AUTOSAR XML (schema 00050)
package /Pkg_DegManager_A/ComponentTypes
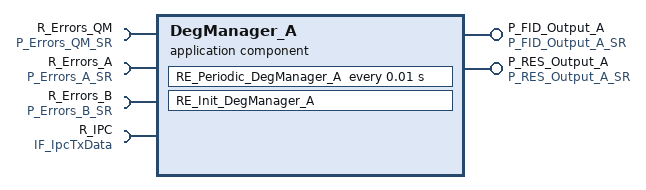
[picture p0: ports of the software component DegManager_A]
  application sw component type DegManager_A
    provide port P_FID_Output_A: nonqueued-sender-com-spec{data-element=FID_A, init-value=constant-reference=init_FID_A}, provided-interface=P_FID_Output_A_SR
    require port R_Errors_QM: nonqueued-receiver-com-spec{data-element=Errors_QM, init-value=constant-reference=init_Errors_QM}, required-interface=P_Errors_QM_SR
    require port R_Errors_A: nonqueued-receiver-com-spec{data-element=Errors_A, init-value=constant-reference=init_Errors_A}, required-interface=P_Errors_A_SR
    require port R_Errors_B: nonqueued-receiver-com-spec{data-element=Errors_B, init-value=constant-reference=init_Errors_B}, required-interface=P_Errors_B_SR
    provide port P_RES_Output_A: nonqueued-sender-com-spec{data-element=RES_A, init-value=constant-reference=init_RES_A}, provided-interface=P_RES_Output_A_SR
    require port R_IPC: client-com-spec=IPC_Write_v, required-interface=IF_IpcTxData
    behavior DegManager_A_InternalBehavior: handle-termination-and-restart=NO-SUPPORT
      timing event TMT_RE_Periodic_DegManager_A: start-on-event=RE_Periodic_DegManager_A, period=0.01
      init event InitEvent: start-on-event=RE_Init_DegManager_A
      port-api-options:
        enable-take-address=false, error-handling=NO-TRANSFORMER-ERROR-HANDLING, indirect-api=false, port=P_FID_Output_A
        enable-take-address=false, error-handling=NO-TRANSFORMER-ERROR-HANDLING, indirect-api=false, port=R_Errors_A
        enable-take-address=false, error-handling=NO-TRANSFORMER-ERROR-HANDLING, indirect-api=false, port=R_Errors_B
        enable-take-address=false, error-handling=NO-TRANSFORMER-ERROR-HANDLING, indirect-api=false, port=R_Errors_QM
        enable-take-address=false, error-handling=NO-TRANSFORMER-ERROR-HANDLING, indirect-api=false, port=P_RES_Output_A
        enable-take-address=false, error-handling=NO-TRANSFORMER-ERROR-HANDLING, indirect-api=false, port=R_IPC
      runnable RE_Periodic_DegManager_A  # Periodic Runnable of Satellite
        data-receive-point-by-arguments:
          access REC_R_Errors_QM_Errors_QM: accessed-variable=R_Errors_QM.Errors_QM
          access REC_R_Errors_A_Errors_A: accessed-variable=R_Errors_A.Errors_A
          access REC_R_Errors_B_Errors_B: accessed-variable=R_Errors_B.Errors_B
        data-send-points:
          access SEND_P_FID_Output_A_FID_A: accessed-variable=P_FID_Output_A.FID_A
          access SEND_P_RES_Output_A_RES_A: accessed-variable=P_RES_Output_A.RES_A
        sync call SC_R_IPC_IPC_Write_v: operation=R_IPC.IPC_Write_v, timeout=0
      runnable RE_Init_DegManager_A  # Init Runnable
  swc implementation DegManager_A_Implementation: programming-language=C, vendor-id=0, behavior=DegManager_A_InternalBehavior
    code-descriptors:
      code Default: artifact-descriptors=autosar-engineering-object=category=SWSRC
